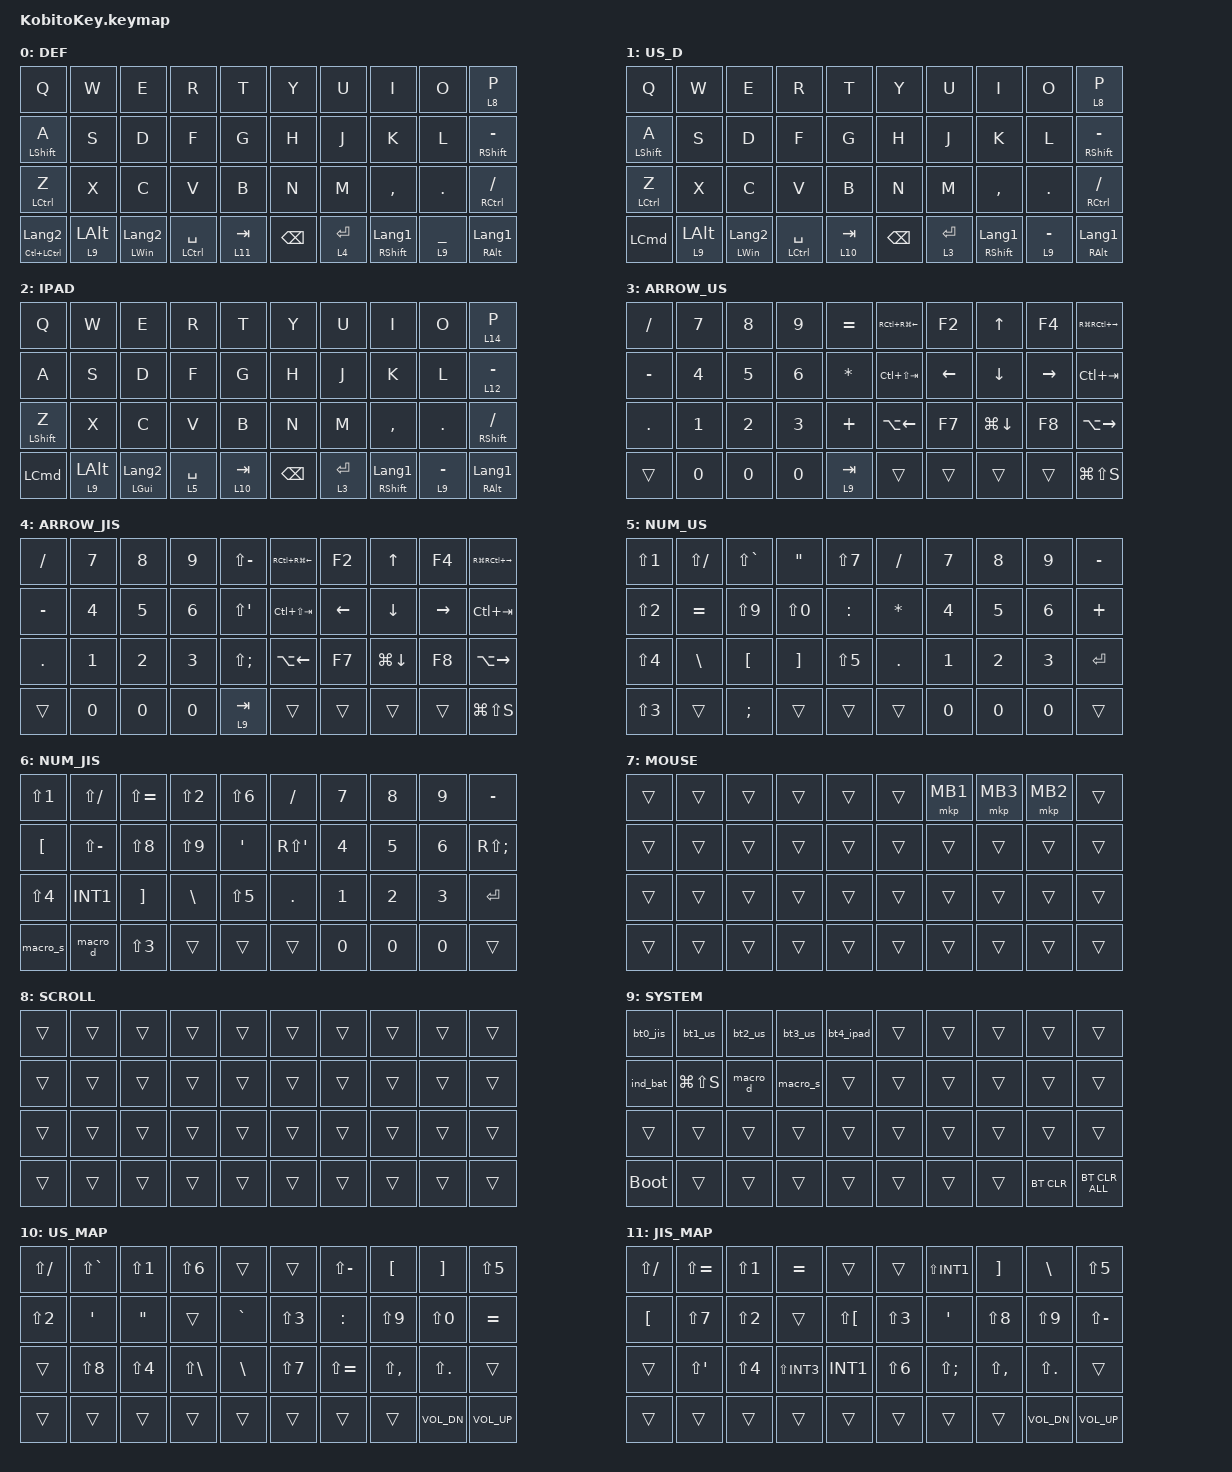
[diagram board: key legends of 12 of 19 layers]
#include <input/processors.dtsi>
#include <behaviors/rgbled_widget.dtsi>
#include <behaviors.dtsi>
#include <dt-bindings/zmk/bt.h>
#include <dt-bindings/zmk/keys.h>
#include <dt-bindings/zmk/pointing.h>

&lt {
    quick-tap-ms = <200>;
    flavor = "balanced";
};

&mt {
    flavor = "balanced";
    quick-tap-ms = <0>;
};

/ {
    combos {
        compatible = "zmk,combos";

        combo_kana {
            timeout-ms = <50>;
            key-positions = <16 17>;
            bindings = <&kp LANG1>;
        };

        combo_kl_lang2 {
            timeout-ms = <50>;
            key-positions = <17 18>;
            bindings = <&kp LANG2>;
        };

        combo_del {
            timeout-ms = <50>;
            key-positions = <8 9>;
            bindings = <&kp DEL>;
        };

        combo_esc {
            timeout-ms = <50>;
            key-positions = <0 1>;
            bindings = <&kp ESC>;
        };

        combo_tab {
            timeout-ms = <50>;
            key-positions = <11 12>;
            bindings = <&kp TAB>;
        };
    };

    macros {
        macro_s: macro_s {
            compatible = "zmk,behavior-macro";
            #binding-cells = <0>;
            wait-ms = <30>;
            tap-ms = <30>;
            bindings = <&kp H &kp O &kp N &kp N &kp A &kp D &kp A &kp I>;
            label = "MACRO_S";
        };

        macro_d: macro_d {
            compatible = "zmk,behavior-macro";
            #binding-cells = <0>;
            wait-ms = <30>;
            tap-ms = <30>;
            bindings = <&kp LS(A) &kp N2 &kp N9 &kp N5 &kp X &kp P>;
            label = "MACRO_D";
        };

        bt0_jis: bt0_jis {
            compatible = "zmk,behavior-macro";
            #binding-cells = <0>;
            wait-ms = <10>;
            tap-ms = <10>;
            bindings = <&bt BT_SEL 0 &to 0>;
            label = "BT0_JIS";
        };

        bt1_us: bt1_us {
            compatible = "zmk,behavior-macro";
            #binding-cells = <0>;
            wait-ms = <10>;
            tap-ms = <10>;
            bindings = <&bt BT_SEL 1 &to 1>;
            label = "BT1_US";
        };

        bt2_us: bt2_us {
            compatible = "zmk,behavior-macro";
            #binding-cells = <0>;
            wait-ms = <10>;
            tap-ms = <10>;
            bindings = <&bt BT_SEL 2 &to 1>;
            label = "BT2_US";
        };

        bt3_us: bt3_us {
            compatible = "zmk,behavior-macro";
            #binding-cells = <0>;
            wait-ms = <10>;
            tap-ms = <10>;
            bindings = <&bt BT_SEL 3 &to 1 &tog 15>;
            label = "BT3_US";
        };

        bt4_ipad: bt4_ipad {
            compatible = "zmk,behavior-macro";
            #binding-cells = <0>;
            wait-ms = <10>;
            tap-ms = <10>;
            bindings = <&bt BT_SEL 4 &to 2>;
            label = "BT4_IPAD";
        };

        ipad_home: ipad_home {
            compatible = "zmk,behavior-macro";
            #binding-cells = <0>;
            wait-ms = <30>;
            tap-ms = <30>;
            bindings =
                <&macro_press>,
                <&kp GLOBE>,
                <&macro_tap>,
                <&kp H>,
                <&macro_release>,
                <&kp GLOBE>;

            label = "IPAD_HOME";
        };

        ipad_full: ipad_full {
            compatible = "zmk,behavior-macro";
            #binding-cells = <0>;
            wait-ms = <30>;
            tap-ms = <30>;
            bindings =
                <&macro_press>,
                <&kp GLOBE>,
                <&macro_tap>,
                <&kp F>,
                <&macro_release>,
                <&kp GLOBE>;

            label = "IPAD_FULL";
        };

        ipad_recent: ipad_recent {
            compatible = "zmk,behavior-macro";
            #binding-cells = <0>;
            wait-ms = <30>;
            tap-ms = <30>;
            bindings =
                <&macro_press>,
                <&kp GLOBE>,
                <&macro_tap>,
                <&kp UP>,
                <&macro_release>,
                <&kp GLOBE>;

            label = "IPAD_RECENT";
        };

        ipad_dock: ipad_dock {
            compatible = "zmk,behavior-macro";
            #binding-cells = <0>;
            wait-ms = <30>;
            tap-ms = <30>;
            bindings =
                <&macro_press>,
                <&kp GLOBE>,
                <&macro_tap>,
                <&kp A>,
                <&macro_release>,
                <&kp GLOBE>;

            label = "IPAD_DOCK";
        };

        ipad_applib: ipad_applib {
            compatible = "zmk,behavior-macro";
            #binding-cells = <0>;
            wait-ms = <30>;
            tap-ms = <30>;
            bindings =
                <&macro_press>,
                <&kp GLOBE &kp LSHIFT>,
                <&macro_tap>,
                <&kp A>,
                <&macro_release>,
                <&kp GLOBE &kp LSHIFT>;

            label = "IPAD_APPLIB";
        };

        ipad_left: ipad_left {
            compatible = "zmk,behavior-macro";
            #binding-cells = <0>;
            wait-ms = <30>;
            tap-ms = <30>;
            bindings =
                <&macro_press>,
                <&kp LCTRL &kp GLOBE>,
                <&macro_tap>,
                <&kp LEFT>,
                <&macro_release>,
                <&kp LCTRL &kp GLOBE>;

            label = "IPAD_LEFT";
        };

        ipad_right: ipad_right {
            compatible = "zmk,behavior-macro";
            #binding-cells = <0>;
            wait-ms = <30>;
            tap-ms = <30>;
            bindings =
                <&macro_press>,
                <&kp LCTRL &kp GLOBE>,
                <&macro_tap>,
                <&kp RIGHT>,
                <&macro_release>,
                <&kp LCTRL &kp GLOBE>;

            label = "IPAD_RIGHT";
        };
    };

    keymap {
        compatible = "zmk,keymap";

        /* [0] DEF (JIS OS用) */

        default_layer {
            label = "DEF";
            bindings = <
&kp Q                            &kp W           &kp E                    &kp R                   &kp T       &kp Y     &kp U        &kp I                       &kp O        &lt 8 P
&mt LEFT_SHIFT A                 &kp S           &kp D                    &kp F                   &kp G       &kp H     &kp J        &kp K                       &kp L        &mt RIGHT_SHIFT MINUS
&mt LEFT_CONTROL Z               &kp X           &kp C                    &kp V                   &kp B       &kp N     &kp M        &kp COMMA                   &kp DOT      &mt RIGHT_CONTROL SLASH
&mt LC(LEFT_CONTROL) LANGUAGE_2  &lt 9 LEFT_ALT  &mt LEFT_WIN LANGUAGE_2  &mt LEFT_CONTROL SPACE  &lt 11 TAB  &kp BSPC  &lt 4 ENTER  &mt RIGHT_SHIFT LANGUAGE_1  &lt 9 UNDER  &mt RIGHT_ALT LANGUAGE_1
            >;
        };

        /* [1] US_D (US OS用) */

        us_defo {
            label = "US_D";
            bindings = <
&kp Q               &kp W           &kp E                    &kp R                   &kp T       &kp Y     &kp U        &kp I                       &kp O        &lt 8 P
&mt LEFT_SHIFT A    &kp S           &kp D                    &kp F                   &kp G       &kp H     &kp J        &kp K                       &kp L        &mt RIGHT_SHIFT MINUS
&mt LEFT_CONTROL Z  &kp X           &kp C                    &kp V                   &kp B       &kp N     &kp M        &kp COMMA                   &kp DOT      &mt RIGHT_CONTROL SLASH
&kp LCMD            &lt 9 LEFT_ALT  &mt LEFT_WIN LANGUAGE_2  &mt LEFT_CONTROL SPACE  &lt 10 TAB  &kp BSPC  &lt 3 ENTER  &mt RIGHT_SHIFT LANGUAGE_1  &lt 9 MINUS  &mt RIGHT_ALT LANGUAGE_1
            >;
        };

        /* [2] IPAD (iPad用US配列: Ctrl位置をCmdに / 「-」長押しでiPad操作レイヤー[12]) */

        ipad_base {
            label = "IPAD";
            bindings = <
&kp Q        &kp W           &kp E                    &kp R        &kp T       &kp Y     &kp U        &kp I                       &kp O        &lt 14 P
&kp A        &kp S           &kp D                    &kp F        &kp G       &kp H     &kp J        &kp K                       &kp L        &lt 12 MINUS
&mt LSHFT Z  &kp X           &kp C                    &kp V        &kp B       &kp N     &kp M        &kp COMMA                   &kp DOT      &mt RSHFT SLASH
&kp LCMD     &lt 9 LEFT_ALT  &mt LEFT_GUI LANGUAGE_2  &lt 5 SPACE  &lt 10 TAB  &kp BSPC  &lt 3 ENTER  &mt RIGHT_SHIFT LANGUAGE_1  &lt 9 MINUS  &mt RIGHT_ALT LANGUAGE_1
            >;
        };

        /* [3] ARROW_US (ENTER長押し / US_D側) */

        ARROW_US {
            label = "ARROW_US";
            bindings = <
&kp SLASH   &kp N7  &kp N8        &kp N9  &kp EQUAL     &kp RC(RG(LEFT))  &kp F2    &kp UP        &kp F4     &kp RG(RC(RIGHT))
&kp MINUS   &kp N4  &kp N5        &kp N6  &kp ASTERISK  &kp LC(LS(TAB))   &kp LEFT  &kp DOWN      &kp RIGHT  &kp LC(TAB)
&kp PERIOD  &kp N1  &kp N2        &kp N3  &kp PLUS      &kp LA(LEFT)      &kp F7    &kp LG(DOWN)  &kp F8     &kp LA(RIGHT)
&trans      &kp N0  &kp NUMBER_0  &kp N0  &lt 9 TAB     &trans            &trans    &trans        &trans     &kp LG(LS(S))
            >;
        };

        /* [4] ARROW_JIS (ENTER長押し / DEF側、表示文字はARROW_USと同じ) */

        ARROW_JIS {
            label = "ARROW_JIS";
            bindings = <
&kp SLASH   &kp N7  &kp N8        &kp N9  &kp LS(MINUS)  &kp RC(RG(LEFT))  &kp F2    &kp UP        &kp F4     &kp RG(RC(RIGHT))
&kp MINUS   &kp N4  &kp N5        &kp N6  &kp LS(SQT)    &kp LC(LS(TAB))   &kp LEFT  &kp DOWN      &kp RIGHT  &kp LC(TAB)
&kp PERIOD  &kp N1  &kp N2        &kp N3  &kp LS(SEMI)   &kp LA(LEFT)      &kp F7    &kp LG(DOWN)  &kp F8     &kp LA(RIGHT)
&trans      &kp N0  &kp NUMBER_0  &kp N0  &lt 9 TAB      &trans            &trans    &trans        &trans     &kp LG(LS(S))
            >;
        };

        /* [5] NUM_US (SPACE長押し / US_D側) */

        NUM_US {
            label = "NUM_US";
            bindings = <
&kp LS(N1)  &kp LS(SLASH)  &kp LS(GRAVE)  &kp DQT     &kp LS(N7)  &kp SLASH     &kp N7  &kp N8  &kp N9        &kp MINUS
&kp LS(N2)  &kp EQUAL      &kp LS(N9)     &kp LS(N0)  &kp COLON   &kp ASTERISK  &kp N4  &kp N5  &kp N6        &kp PLUS
&kp LS(N4)  &kp BSLH       &kp LBKT       &kp RBKT    &kp LS(N5)  &kp DOT       &kp N1  &kp N2  &kp N3        &kp ENTER
&kp LS(N3)  &trans         &kp SEMI       &trans      &trans      &trans        &kp N0  &kp N0  &kp NUMBER_0  &trans
            >;
        };

        /* [6] NUM_JIS (SPACE長押し / DEF側、表示文字はNUM_USと同じ) */

        NUM_JIS {
            label = "NUM_JIS";
            bindings = <
&kp LS(N1)  &kp LS(SLASH)  &kp LS(EQUAL)  &kp LS(N2)  &kp LS(N6)  &kp SLASH    &kp N7  &kp N8  &kp N9        &kp MINUS
&kp LBKT    &kp LS(MINUS)  &kp LS(N8)     &kp LS(N9)  &kp SQT     &kp RS(SQT)  &kp N4  &kp N5  &kp N6        &kp RS(SEMICOLON)
&kp LS(N4)  &kp INT1       &kp RBKT       &kp BSLH    &kp LS(N5)  &kp DOT      &kp N1  &kp N2  &kp N3        &kp ENTER
&macro_s    &macro_d       &kp LS(N3)     &trans      &trans      &trans       &kp N0  &kp N0  &kp NUMBER_0  &trans
            >;
        };

        /* [7] MOUSE (自動発動は既存の小人キー方式、5秒でレイヤーを抜ける) */

        MOUSE {
            label = "MOUSE";
            bindings = <
&trans  &trans  &trans  &trans  &trans  &trans  &mkp MB1  &mkp MB3  &mkp MB2  &trans
&trans  &trans  &trans  &trans  &trans  &trans  &trans    &trans    &trans    &trans
&trans  &trans  &trans  &trans  &trans  &trans  &trans    &trans    &trans    &trans
&trans  &trans  &trans  &trans  &trans  &trans  &trans    &trans    &trans    &trans
            >;
        };

        /* [8] SCROLL (Pキー長押しで直接呼び出し) */

        SCROLL {
            label = "SCROLL";
            bindings = <
&trans  &trans  &trans  &trans  &trans  &trans  &trans  &trans  &trans  &trans
&trans  &trans  &trans  &trans  &trans  &trans  &trans  &trans  &trans  &trans
&trans  &trans  &trans  &trans  &trans  &trans  &trans  &trans  &trans  &trans
&trans  &trans  &trans  &trans  &trans  &trans  &trans  &trans  &trans  &trans
            >;
        };

        /* [9] SYSTEM (BT選択・マクロ・bootloader) */

        SYSTEM {
            label = "SYSTEM";
            bindings = <
&bt0_jis     &bt1_us        &bt2_us   &bt3_us   &bt4_ipad  &trans  &trans  &trans  &trans      &trans
&ind_bat     &kp LG(LS(S))  &macro_d  &macro_s  &trans     &trans  &trans  &trans  &trans      &trans
&trans       &trans         &trans    &trans    &trans     &trans  &trans  &trans  &trans      &trans
&bootloader  &trans         &trans    &trans    &trans     &trans  &trans  &trans  &bt BT_CLR  &bt BT_CLR_ALL
            >;
        };

        /* [10] US_MAP (TAB長押し / US_D側) */

        US_MAP {
            label = "US_MAP";
            bindings = <
&kp LS(SLASH)  &kp LS(GRAVE)  &kp LS(N1)  &kp LS(N6)    &trans     &trans      &kp LS(MINUS)  &kp LBKT       &kp RBKT      &kp LS(N5)
&kp LS(N2)     &kp SQT        &kp DQT     &trans        &kp GRAVE  &kp LS(N3)  &kp COLON      &kp LS(N9)     &kp LS(N0)    &kp EQUAL
&trans         &kp LS(N8)     &kp LS(N4)  &kp LS(BSLH)  &kp BSLH   &kp LS(N7)  &kp LS(EQUAL)  &kp LS(COMMA)  &kp LS(DOT)   &trans
&trans         &trans         &trans      &trans        &trans     &trans      &trans         &trans         &kp C_VOL_DN  &kp C_VOL_UP
            >;
        };

        /* [11] JIS_MAP (TAB長押し / DEF側、表示文字はUS_MAPと同じ) */

        JIS_MAP {
            label = "JIS_MAP";
            bindings = <
&kp LS(SLASH)  &kp LS(EQUAL)  &kp LS(N1)  &kp EQUAL     &trans        &trans      &kp LS(INT1)  &kp RBKT       &kp BSLH      &kp LS(N5)
&kp LBKT       &kp LS(N7)     &kp LS(N2)  &trans        &kp LS(LBKT)  &kp LS(N3)  &kp SQT       &kp LS(N8)     &kp LS(N9)    &kp LS(MINUS)
&trans         &kp LS(SQT)    &kp LS(N4)  &kp LS(INT3)  &kp INT1      &kp LS(N6)  &kp LS(SEMI)  &kp LS(COMMA)  &kp LS(DOT)   &trans
&trans         &trans         &trans      &trans        &trans        &trans      &trans        &trans         &kp C_VOL_DN  &kp C_VOL_UP
            >;
        };

        /* [12] IPAD_ACT (右手だけでウィンドウ/アプリ操作 / 「-」長押しの間だけ有効)
         * Y 前のアプリ  U 最近の一覧  I 全画面  O Dock
         * H ホーム  J 左半分  K 最小化  L 右半分
         * N 検索  , App Library  . 閉じる
         */

        ipad_act {
            label = "IPAD_ACT";
            bindings = <
&trans  &trans  &trans  &trans  &trans  &kp LG(TAB)    &ipad_recent  &ipad_full    &ipad_dock   &trans
&trans  &trans  &trans  &trans  &trans  &ipad_home     &ipad_left    &kp LG(M)     &ipad_right  &trans
&trans  &trans  &trans  &trans  &trans  &kp LG(SPACE)  &trans        &ipad_applib  &kp LG(W)    &trans
&trans  &trans  &trans  &trans  &trans  &trans         &trans        &trans        &trans       &trans
            >;
        };

        /* [13] NUM_US_OLD / [14] NUM_JIS_OLD: 数字+記号を一緒にする前の数字レイヤー(復元) */

        num_us_old {
            label = "NUM_US_OLD";
            bindings = <
&kp PAGE_UP  &kp F2    &kp UP    &kp F4     &kp MINUS     &kp SLASH     &kp N7  &kp N8  &kp N9        &kp MINUS
&trans       &kp LEFT  &kp DOWN  &kp RIGHT  &kp LS(SEMI)  &kp ASTERISK  &kp N4  &kp N5  &kp N6        &kp PLUS
&kp N0       &kp F7    &kp F8    &kp F11    &trans        &kp DOT       &kp N1  &kp N2  &kp N3        &kp ENTER
&trans       &trans    &trans    &trans     &trans        &trans        &kp N0  &kp N0  &kp NUMBER_0  &trans
            >;
        };

        /* [14] SCROLL_IPAD (iPad/iPhone用: 「P」長押し。スクロールの上下反転なし) */

        scroll_ipad {
            label = "SCROLL_IPAD";
            bindings = <
&trans  &trans  &trans  &trans  &trans  &trans  &trans  &trans  &trans  &trans
&trans  &trans  &trans  &trans  &trans  &trans  &trans  &trans  &trans  &trans
&trans  &trans  &trans  &trans  &trans  &trans  &trans  &trans  &trans  &trans
&trans  &trans  &trans  &trans  &trans  &trans  &trans  &trans  &trans  &trans
            >;
        };

        /* [15] MAC_BASE (Mac用の差分レイヤー: US配列(レイヤー1)の上に重ねる / BT3で &tog 15)
         * 位置30,33,34,36以外は透過。MOUSE(7)・SYSTEM(9)より番号が大きいので、透過にしてそれらを隠さないようにする */

        mac_base {
            label = "MAC_BASE";
            bindings = <
&trans                           &trans  &trans  &trans              &trans      &trans  &trans        &trans  &trans  &trans
&trans                           &trans  &trans  &trans              &trans      &trans  &trans        &trans  &trans  &trans
&trans                           &trans  &trans  &trans              &trans      &trans  &trans        &trans  &trans  &trans
&mt LC(LEFT_CONTROL) LANGUAGE_2  &trans  &trans  &mt LEFT_GUI SPACE  &lt 17 TAB  &trans  &lt 16 ENTER  &trans  &trans  &trans
            >;
        };

        /* [16] MAC_ARROW (Mac用 / ENTER長押し) */

        mac_ARROW {
            label = "MAC_ARROW";
            bindings = <
&kp SLASH   &kp N7  &kp N8        &kp N9        &kp EQUAL     &kp LC(LEFT)     &kp F2    &kp UP     &kp F4     &kp LC(RIGHT)
&kp MINUS   &kp N4  &kp N5        &kp N6        &kp ASTERISK  &kp LC(LS(TAB))  &kp LEFT  &kp DOWN   &kp RIGHT  &kp LC(TAB)
&kp PERIOD  &kp N1  &kp N2        &kp N3        &kp PLUS      &kp LG(LBKT)     &kp F7    &kp LG(M)  &kp F8     &kp LG(RBKT)
&trans      &kp N0  &kp NUMBER_0  &kp NUMBER_0  &lt 18 TAB    &trans           &trans    &trans     &trans     &kp LG(LS(N4))
            >;
        };

        /* [17] MAC_MAP (Mac用 / SPACE長押し) */

        mac_MAP {
            label = "MAC_MAP";
            bindings = <
&kp LS(SLASH)  &kp LS(GRAVE)  &kp LS(N1)     &kp LS(N6)     &trans         &trans         &kp LS(MINUS)  &kp LBKT       &kp RBKT       &kp LS(N5)
&kp LS(N2)     &kp SQT        &kp DQT        &trans         &kp GRAVE      &kp LS(N3)     &kp COLON      &kp LS(N9)     &kp LS(N0)     &kp EQUAL
&trans         &kp LS(N8)     &kp LS(N4)     &kp LS(BSLH)   &kp BSLH       &kp LS(N7)     &kp LS(EQUAL)  &kp LS(COMMA)  &kp LS(DOT)    &trans
&trans         &trans         &trans         &trans         &trans         &trans         &trans         &trans         &kp C_VOL_DN   &kp C_VOL_UP
            >;
        };

        /* [18] MAC_SYSTEM (Mac用 / ARROW(16)中のSpace位置長押し。16より優先させるため透過なし) */

        mac_SYSTEM {
            label = "MAC_SYSTEM";
            bindings = <
&bt0_jis     &bt1_us         &bt2_us   &bt3_us   &bt4_ipad  &none  &none  &none  &none       &none
&ind_bat     &kp LG(LS(N4))  &macro_d  &macro_s  &none      &none  &none  &none  &none       &none
&none        &none           &none     &none     &none      &none  &none  &none  &none       &none
&bootloader  &none           &none     &none     &none      &none  &none  &none  &bt BT_CLR  &bt BT_CLR_ALL
            >;
        };
    };
};
